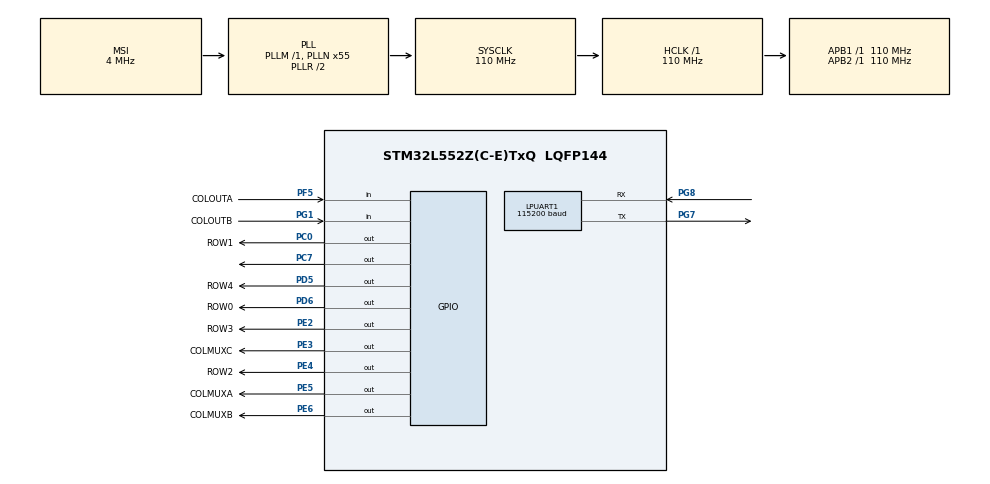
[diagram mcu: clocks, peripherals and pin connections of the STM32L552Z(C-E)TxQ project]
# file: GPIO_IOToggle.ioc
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LPUART1.BaudRate=115200
Mcu.Family=STM32L5
Mcu.Name=STM32L552Z(C-E)TxQ
Mcu.Package=LQFP144
NVIC.PriorityGroup=NVIC_PRIORITYGROUP_3
PC0.GPIO_Label=ROW1
PC0.GPIO_PuPd=GPIO_PULLDOWN
PC0.PinState=GPIO_PIN_RESET
PC0.Signal=GPIO_Output
PC7.GPIO_ModeDefaultOutputPP=GPIO_MODE_OUTPUT_PP
PC7.GPIO_PuPd=GPIO_PULLUP
PC7.GPIO_Speed=GPIO_SPEED_FREQ_VERY_HIGH
PC7.PinState=GPIO_PIN_RESET
PC7.Signal=GPIO_Output
PD5.GPIO_Label=ROW4
PD5.GPIO_PuPd=GPIO_PULLDOWN
PD5.PinState=GPIO_PIN_RESET
PD5.Signal=GPIO_Output
PD6.GPIO_Label=ROW0
PD6.GPIO_PuPd=GPIO_PULLDOWN
PD6.PinState=GPIO_PIN_RESET
PD6.Signal=GPIO_Output
PE2.GPIO_Label=ROW3
PE2.GPIO_PuPd=GPIO_PULLDOWN
PE2.PinState=GPIO_PIN_RESET
PE2.Signal=GPIO_Output
PE3.GPIO_Label=COLMUXC
PE3.Signal=GPIO_Output
PE4.GPIO_Label=ROW2
PE4.GPIO_PuPd=GPIO_PULLDOWN
PE4.PinState=GPIO_PIN_RESET
PE4.Signal=GPIO_Output
PE5.GPIO_Label=COLMUXA
PE5.PinState=GPIO_PIN_RESET
PE5.Signal=GPIO_Output
PE6.GPIO_Label=COLMUXB
PE6.Signal=GPIO_Output
PF5.GPIO_Label=COLOUTA
PF5.Signal=GPIO_Input
PG1.GPIO_Label=COLOUTB
PG1.Signal=GPIO_Input
PG7.Mode=Asynchronous
PG7.Signal=LPUART1_TX
PG8.Mode=Asynchronous
PG8.Signal=LPUART1_RX
ProjectManager.HeapSize=0x200
ProjectManager.StackSize=0x400
ProjectManager.TargetToolchain=STM32CubeIDE
RCC.AHBFreq_Value=110000000
RCC.APB1Freq_Value=110000000
RCC.APB1TimFreq_Value=110000000
RCC.APB2Freq_Value=110000000
RCC.APB2TimFreq_Value=110000000
RCC.CortexFreq_Value=110000000
RCC.HCLKFreq_Value=110000000
RCC.HSE_VALUE=16000000
RCC.HSI48_VALUE=48000000
RCC.HSI_VALUE=16000000
RCC.LSE_VALUE=32768
RCC.MSI_VALUE=4000000
RCC.PLLN=55
RCC.SYSCLKFreq_VALUE=110000000
RCC.SYSCLKSource=RCC_SYSCLKSOURCE_PLLCLK
RCC.VCOOutputFreq_Value=220000000
VP_ICACHE_VS_ICACHE.Mode=DirectMappedCache
VP_PWR_VS_DBSignals.Mode=DisableDeadBatterySignals
VP_PWR_VS_SECSignals.Mode=Security/Privilege
board=NUCLEO-L552ZE-Q

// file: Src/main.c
/* USER CODE BEGIN Header */
/**
  ******************************************************************************
  * @file    GPIO/GPIO_IOToggle/Src/main.c
  * @author  MCD Application Team
  * @brief   This example describes how to configure and use GPIOs through
  *          the STM32L5xx HAL API.
  ******************************************************************************
  * @attention
  *
  * Copyright (c) 2019 STMicroelectronics.
  * All rights reserved.
  *
  * This software is licensed under terms that can be found in the LICENSE file
  * in the root directory of this software component.
  * If no LICENSE file comes with this software, it is provided AS-IS.
  *
  ******************************************************************************
  */
/* USER CODE END Header */
#include "main.h"

UART_HandleTypeDef hlpuart1;

void SystemClock_Config(void);
static void MX_GPIO_Init(void);
static void MX_ICACHE_Init(void);
static void MX_LPUART1_UART_Init(void);

uint8_t matrix[5][14][6] = {
		{"Esc", "1", "2", "3", "4", "5", "6", "7", "8", "9", "0", "=", "-", "Back"},
		{"Tab","Q","W","E","R","T","Y","U","I","O","P","[","]","\\"},
		{"Caps","A","S","D","F","G","H","J","K","L",";","'","\n\r","Up"},
		{"LShift","Z","X","C","V","B","N","M",",",".","/","RShift","Left","Down"},
		{"LCtrl","Win","LAlt","", "", " ","","","", "RAlt","Fn","Menu","RCtrl","Right"},
};

uint8_t lastState[5][14];

int main(void)
{

  /* MCU Configuration--------------------------------------------------------*/

  /* Reset of all peripherals, Initializes the Flash interface and the Systick. */
  HAL_Init();

  /* Configure the system clock */
  SystemClock_Config();

  /* Initialize all configured peripherals */
  MX_GPIO_Init();
  MX_ICACHE_Init();
  MX_LPUART1_UART_Init();
  /* USER CODE BEGIN 2 */

  HAL_GPIO_WritePin(GPIOD, GPIO_PIN_6, GPIO_PIN_RESET);
  HAL_GPIO_WritePin(GPIOC, GPIO_PIN_0, GPIO_PIN_RESET);
  HAL_GPIO_WritePin(GPIOE, GPIO_PIN_4, GPIO_PIN_RESET);
  HAL_GPIO_WritePin(GPIOE, GPIO_PIN_2, GPIO_PIN_RESET);
  HAL_GPIO_WritePin(GPIOD, GPIO_PIN_5, GPIO_PIN_RESET);

  uint8_t buff[] = "Hello!\n\r";

  HAL_UART_Transmit(&hlpuart1, buff, sizeof(buff), 100);

  /* USER CODE END 2 */

  /* Infinite loop */
  /* USER CODE BEGIN WHILE */

  //

  while (1)
  {
	uint8_t wrote = 0;
	HAL_GPIO_TogglePin(GPIOC, GPIO_PIN_7);

    /* USER CODE END WHILE */

    // iterate through all rows and columns
    for (int row = 0; row < 5; row++){

    	//HAL_GPIO_WritePin(ROW0_GPIO_Port, ROW0_Pin, GPIO_PIN_SET);

	  HAL_GPIO_WritePin(ROW0_GPIO_Port, ROW0_Pin, GPIO_PIN_RESET);
	  HAL_GPIO_WritePin(ROW1_GPIO_Port, ROW1_Pin, GPIO_PIN_RESET);
	  HAL_GPIO_WritePin(ROW2_GPIO_Port, ROW2_Pin, GPIO_PIN_RESET);
	  HAL_GPIO_WritePin(ROW3_GPIO_Port, ROW3_Pin, GPIO_PIN_RESET);
	  HAL_GPIO_WritePin(ROW4_GPIO_Port, ROW4_Pin, GPIO_PIN_RESET);

    	switch (row){
    		case 0:
    			HAL_GPIO_WritePin(ROW0_GPIO_Port, ROW0_Pin, GPIO_PIN_SET);
    			break;
    		case 1:
    			HAL_GPIO_WritePin(ROW1_GPIO_Port, ROW1_Pin, GPIO_PIN_SET);
				break;
    		case 2:
    			HAL_GPIO_WritePin(ROW2_GPIO_Port, ROW2_Pin, GPIO_PIN_SET);
				break;
    		case 3:
    			HAL_GPIO_WritePin(ROW3_GPIO_Port, ROW3_Pin, GPIO_PIN_SET);
				break;
    		case 4:
    			HAL_GPIO_WritePin(ROW4_GPIO_Port, ROW4_Pin, GPIO_PIN_SET);
				break;
    	}

    	 //write to muxes
//		HAL_GPIO_WritePin(COLMUXA_GPIO_Port, COLMUXA_Pin, 0);
//		HAL_GPIO_WritePin(COLMUXB_GPIO_Port, COLMUXB_Pin, 1);
//		HAL_GPIO_WritePin(COLMUXC_GPIO_Port, COLMUXC_Pin, 0);
//		HAL_Delay(1);
//		// read from muxes
//		if (HAL_GPIO_ReadPin(COLOUTA_GPIO_Port, COLOUTA_Pin)){
//			HAL_UART_Transmit(&hlpuart1, matrix[row][4], sizeof(matrix[row][4 + 0]), 100);
//			HAL_UART_Transmit(&hlpuart1, " ", sizeof(" "), 100);
//		}
//		if (HAL_GPIO_ReadPin(COLOUTB_GPIO_Port, COLOUTB_Pin)){
//			HAL_UART_Transmit(&hlpuart1, matrix[row][4 + 1], sizeof(matrix[row][4 + 1]), 100);
//			HAL_UART_Transmit(&hlpuart1, " ", sizeof(" "), 100);
//		}

    	for (int col = 0; col < 14; col += 2){

    		// write to muxes
    		HAL_GPIO_WritePin(COLMUXA_GPIO_Port, COLMUXA_Pin, (col >> 1) & 0b001);
			HAL_GPIO_WritePin(COLMUXB_GPIO_Port, COLMUXB_Pin, (col >> 1) & 0b010);
			HAL_GPIO_WritePin(COLMUXC_GPIO_Port, COLMUXC_Pin, (col >> 1) & 0b100);
			// read from muxes
			if (HAL_GPIO_ReadPin(COLOUTA_GPIO_Port, COLOUTA_Pin) && lastState[row][col + 0] == 0){
				HAL_UART_Transmit(&hlpuart1, matrix[row][col + 0], sizeof(matrix[row][col + 0]), 100);
				//HAL_UART_Transmit(&hlpuart1, " ", sizeof(" "), 100);
				wrote = 1;
			}
			if (HAL_GPIO_ReadPin(COLOUTB_GPIO_Port, COLOUTB_Pin) && lastState[row][col + 1] == 0){
				HAL_UART_Transmit(&hlpuart1, matrix[row][col + 1], sizeof(matrix[row][col + 1]), 100);
				//HAL_UART_Transmit(&hlpuart1, " ", sizeof(" "), 100);
				wrote = 1;
			}

			lastState[row][col + 0] = HAL_GPIO_ReadPin(COLOUTA_GPIO_Port, COLOUTA_Pin);
			lastState[row][col + 1] = HAL_GPIO_ReadPin(COLOUTB_GPIO_Port, COLOUTB_Pin);
    	}
    }
    if (wrote){
    	//HAL_UART_Transmit(&hlpuart1, "\n\r", sizeof("\n\r"), 100);
    }

    HAL_Delay(1);
  }
  /* USER CODE END 3 */
}

void SystemClock_Config(void)
{
  RCC_OscInitTypeDef RCC_OscInitStruct = {0};
  RCC_ClkInitTypeDef RCC_ClkInitStruct = {0};

  /** Configure the main internal regulator output voltage
  */
  if (HAL_PWREx_ControlVoltageScaling(PWR_REGULATOR_VOLTAGE_SCALE0) != HAL_OK)
  {
    Error_Handler();
  }

  /** Initializes the RCC Oscillators according to the specified parameters
  * in the RCC_OscInitTypeDef structure.
  */
  RCC_OscInitStruct.OscillatorType = RCC_OSCILLATORTYPE_MSI;
  RCC_OscInitStruct.MSIState = RCC_MSI_ON;
  RCC_OscInitStruct.MSICalibrationValue = RCC_MSICALIBRATION_DEFAULT;
  RCC_OscInitStruct.MSIClockRange = RCC_MSIRANGE_6;
  RCC_OscInitStruct.PLL.PLLState = RCC_PLL_ON;
  RCC_OscInitStruct.PLL.PLLSource = RCC_PLLSOURCE_MSI;
  RCC_OscInitStruct.PLL.PLLM = 1;
  RCC_OscInitStruct.PLL.PLLN = 55;
  RCC_OscInitStruct.PLL.PLLP = RCC_PLLP_DIV7;
  RCC_OscInitStruct.PLL.PLLQ = RCC_PLLQ_DIV2;
  RCC_OscInitStruct.PLL.PLLR = RCC_PLLR_DIV2;
  if (HAL_RCC_OscConfig(&RCC_OscInitStruct) != HAL_OK)
  {
    Error_Handler();
  }

  /** Initializes the CPU, AHB and APB buses clocks
  */
  RCC_ClkInitStruct.ClockType = RCC_CLOCKTYPE_HCLK|RCC_CLOCKTYPE_SYSCLK
                              |RCC_CLOCKTYPE_PCLK1|RCC_CLOCKTYPE_PCLK2;
  RCC_ClkInitStruct.SYSCLKSource = RCC_SYSCLKSOURCE_PLLCLK;
  RCC_ClkInitStruct.AHBCLKDivider = RCC_SYSCLK_DIV1;
  RCC_ClkInitStruct.APB1CLKDivider = RCC_HCLK_DIV1;
  RCC_ClkInitStruct.APB2CLKDivider = RCC_HCLK_DIV1;

  if (HAL_RCC_ClockConfig(&RCC_ClkInitStruct, FLASH_LATENCY_5) != HAL_OK)
  {
    Error_Handler();
  }
}

static void MX_ICACHE_Init(void)
{

  /** Enable instruction cache in 1-way (direct mapped cache)
  */
  if (HAL_ICACHE_ConfigAssociativityMode(ICACHE_1WAY) != HAL_OK)
  {
    Error_Handler();
  }
  if (HAL_ICACHE_Enable() != HAL_OK)
  {
    Error_Handler();
  }

}

static void MX_LPUART1_UART_Init(void)
{

  hlpuart1.Instance = LPUART1;
  hlpuart1.Init.BaudRate = 115200;
  hlpuart1.Init.WordLength = UART_WORDLENGTH_8B;
  hlpuart1.Init.StopBits = UART_STOPBITS_1;
  hlpuart1.Init.Parity = UART_PARITY_NONE;
  hlpuart1.Init.Mode = UART_MODE_TX_RX;
  hlpuart1.Init.HwFlowCtl = UART_HWCONTROL_NONE;
  hlpuart1.Init.OneBitSampling = UART_ONE_BIT_SAMPLE_DISABLE;
  hlpuart1.Init.ClockPrescaler = UART_PRESCALER_DIV1;
  hlpuart1.AdvancedInit.AdvFeatureInit = UART_ADVFEATURE_NO_INIT;
  hlpuart1.FifoMode = UART_FIFOMODE_DISABLE;
  if (HAL_UART_Init(&hlpuart1) != HAL_OK)
  {
    Error_Handler();
  }
  if (HAL_UARTEx_SetTxFifoThreshold(&hlpuart1, UART_TXFIFO_THRESHOLD_1_8) != HAL_OK)
  {
    Error_Handler();
  }
  if (HAL_UARTEx_SetRxFifoThreshold(&hlpuart1, UART_RXFIFO_THRESHOLD_1_8) != HAL_OK)
  {
    Error_Handler();
  }
  if (HAL_UARTEx_DisableFifoMode(&hlpuart1) != HAL_OK)
  {
    Error_Handler();
  }

}

static void MX_GPIO_Init(void)
{
  GPIO_InitTypeDef GPIO_InitStruct = {0};

  /* GPIO Ports Clock Enable */
  __HAL_RCC_GPIOE_CLK_ENABLE();
  __HAL_RCC_GPIOF_CLK_ENABLE();
  __HAL_RCC_GPIOC_CLK_ENABLE();
  __HAL_RCC_GPIOG_CLK_ENABLE();
  HAL_PWREx_EnableVddIO2();
  __HAL_RCC_GPIOD_CLK_ENABLE();

  /*Configure GPIO pin Output Level */
  HAL_GPIO_WritePin(GPIOE, ROW3_Pin|COLMUXC_Pin|ROW2_Pin|COLMUXA_Pin
                          |COLMUXB_Pin, GPIO_PIN_RESET);

  /*Configure GPIO pin Output Level */
  HAL_GPIO_WritePin(GPIOC, ROW1_Pin|GPIO_PIN_7, GPIO_PIN_RESET);

  /*Configure GPIO pin Output Level */
  HAL_GPIO_WritePin(GPIOD, ROW4_Pin|ROW0_Pin, GPIO_PIN_RESET);

  /*Configure GPIO pins : ROW3_Pin ROW2_Pin */
  GPIO_InitStruct.Pin = ROW3_Pin|ROW2_Pin;
  GPIO_InitStruct.Mode = GPIO_MODE_OUTPUT_PP;
  GPIO_InitStruct.Pull = GPIO_PULLDOWN;
  GPIO_InitStruct.Speed = GPIO_SPEED_FREQ_LOW;
  HAL_GPIO_Init(GPIOE, &GPIO_InitStruct);

  /*Configure GPIO pins : COLMUXC_Pin COLMUXA_Pin COLMUXB_Pin */
  GPIO_InitStruct.Pin = COLMUXC_Pin|COLMUXA_Pin|COLMUXB_Pin;
  GPIO_InitStruct.Mode = GPIO_MODE_OUTPUT_PP;
  GPIO_InitStruct.Pull = GPIO_NOPULL;
  GPIO_InitStruct.Speed = GPIO_SPEED_FREQ_LOW;
  HAL_GPIO_Init(GPIOE, &GPIO_InitStruct);

  /*Configure GPIO pin : COLOUTA_Pin */
  GPIO_InitStruct.Pin = COLOUTA_Pin;
  GPIO_InitStruct.Mode = GPIO_MODE_INPUT;
  GPIO_InitStruct.Pull = GPIO_NOPULL;
  HAL_GPIO_Init(COLOUTA_GPIO_Port, &GPIO_InitStruct);

  /*Configure GPIO pin : ROW1_Pin */
  GPIO_InitStruct.Pin = ROW1_Pin;
  GPIO_InitStruct.Mode = GPIO_MODE_OUTPUT_PP;
  GPIO_InitStruct.Pull = GPIO_PULLDOWN;
  GPIO_InitStruct.Speed = GPIO_SPEED_FREQ_LOW;
  HAL_GPIO_Init(ROW1_GPIO_Port, &GPIO_InitStruct);

  /*Configure GPIO pin : COLOUTB_Pin */
  GPIO_InitStruct.Pin = COLOUTB_Pin;
  GPIO_InitStruct.Mode = GPIO_MODE_INPUT;
  GPIO_InitStruct.Pull = GPIO_NOPULL;
  HAL_GPIO_Init(COLOUTB_GPIO_Port, &GPIO_InitStruct);

  /*Configure GPIO pin : PC7 */
  GPIO_InitStruct.Pin = GPIO_PIN_7;
  GPIO_InitStruct.Mode = GPIO_MODE_OUTPUT_PP;
  GPIO_InitStruct.Pull = GPIO_PULLUP;
  GPIO_InitStruct.Speed = GPIO_SPEED_FREQ_VERY_HIGH;
  HAL_GPIO_Init(GPIOC, &GPIO_InitStruct);

  /*Configure GPIO pins : ROW4_Pin ROW0_Pin */
  GPIO_InitStruct.Pin = ROW4_Pin|ROW0_Pin;
  GPIO_InitStruct.Mode = GPIO_MODE_OUTPUT_PP;
  GPIO_InitStruct.Pull = GPIO_PULLDOWN;
  GPIO_InitStruct.Speed = GPIO_SPEED_FREQ_LOW;
  HAL_GPIO_Init(GPIOD, &GPIO_InitStruct);

}

void Error_Handler(void)
{
  while (1)
  {
  }
}
